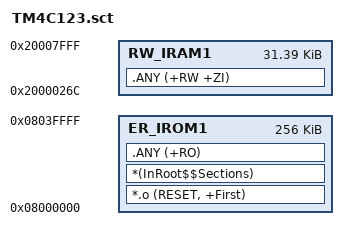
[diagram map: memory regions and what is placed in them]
; *************************************************************
; *** Scatter-Loading Description File generated by uVision ***
; *************************************************************

LR_IROM1 0x08000000 0x00040000  {    ; load region size_region
  ER_IROM1 0x08000000 0x00040000 {  ; load address = execution address
   *.o (RESET, +First)
   *(InRoot$$Sections)
   .ANY (+RO)
  }
  RW_IRAM1 0x2000026c 0x00007D94 {
   .ANY (+RW +ZI)
  }
}

